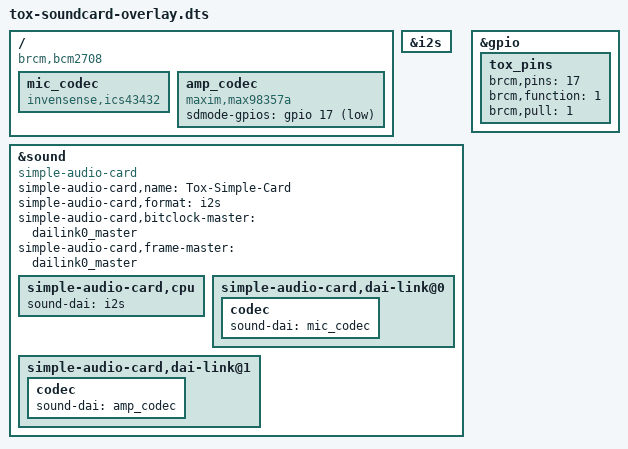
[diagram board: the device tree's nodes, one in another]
// Definitions for Nyumaya Card
/dts-v1/;
/plugin/;

/ {
	compatible = "brcm,bcm2708";
	
	fragment@0 {
		target = <&i2s>;
		__overlay__ {
			status = "okay";
		};
	};

	fragment@1 {
		target-path = "/";
		__overlay__ {
			mic_codec {
				#sound-dai-cells = <0>;
				compatible = "invensense,ics43432";
				status = "okay";
			};
		};
	};

	fragment@2 {
		target-path = "/";
		__overlay__ {
			amp_codec {
				#sound-dai-cells = <0>;
				compatible = "maxim,max98357a";
				sdmode-gpios = <&gpio 17 1>;
				status = "okay";
			};
		};
	};

	fragment@3 {
		target = <&sound>;
		__overlay__ {
			compatible = "simple-audio-card";
			simple-audio-card,name = "Tox-Simple-Card";
			simple-audio-card,format = "i2s";
			status = "okay";
			simple-audio-card,bitclock-master = <&dailink0_master>;
			simple-audio-card,frame-master = <&dailink0_master>;
			simple-audio-card,cpu {
				sound-dai = <&i2s>;
			};


			simple-audio-card,dai-link@0 {		/* I2S - MIC */

				codec {
					sound-dai = <&mic_codec>;
				};
			};

			simple-audio-card,dai-link@1 {		/* I2S AMP */
				codec {
					sound-dai = <&amp_codec>;
				};
			};
		};
	};





	fragment@4 {
			target = <&gpio>;
			__overlay__ {
				tox_pins: tox_pins {
					brcm,pins = <17>;
					brcm,function = <1>; // out in
					brcm,pull = <1>; // off down
				};
			};
	};

	__overrides__ {
		gpio_mute_pin =  <&tox_pins>,"brcm,pins:0";
	};





};
